# SF32LB55x register map
File version: 1.0
CPU: CM33 r0p1, little endian, MPU, FPU, 3 interrupt priority bits
Registers are 32-bit, read-write, reset 0x0 unless marked. A register's access mark holds for its fields unless they carry their own. Offsets are from the block's base; [hi:lo] are bit positions; {n}, {i} and the like mark numbered series; 'fields as' and 'values as' point back to an identical list.

## EPIC
Base 0x40007000
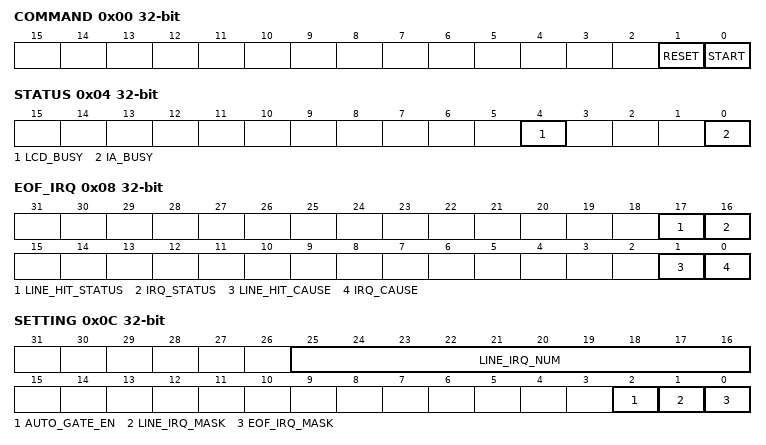
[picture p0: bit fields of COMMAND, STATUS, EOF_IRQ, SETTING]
0x00 COMMAND
  [1] RESET — 1: reset the whole graphics 0: release the reset
  [0] START — write 1 to trigger the lcd interface block
0x04 STATUS
  [4] LCD_BUSY — LCD controll busy flag
  [0] IA_BUSY — Graphics accelerator busy flag
0x08 EOF_IRQ
  [17] LINE_HIT_STATUS — raw status of line hit interrupt
  [16] IRQ_STATUS — raw status of end of frame interrupt
  [1] LINE_HIT_CAUSE — line hit interrupt, can be masked by LINE_IRQ_MASK
  [0] IRQ_CAUSE — end of frame interrupt, can be masked by EOF_IRQ_MASK
0x0C SETTING
  [25:16] LINE_IRQ_NUM — canvas line hit interrupt line number
  [2] AUTO_GATE_EN — auto clock gating enable
  [1] LINE_IRQ_MASK — canvas line hit interrupt mask, 0: mask the interrupt
  [0] EOF_IRQ_MASK — end of frame interrupt mask, 0: mask the interrupt
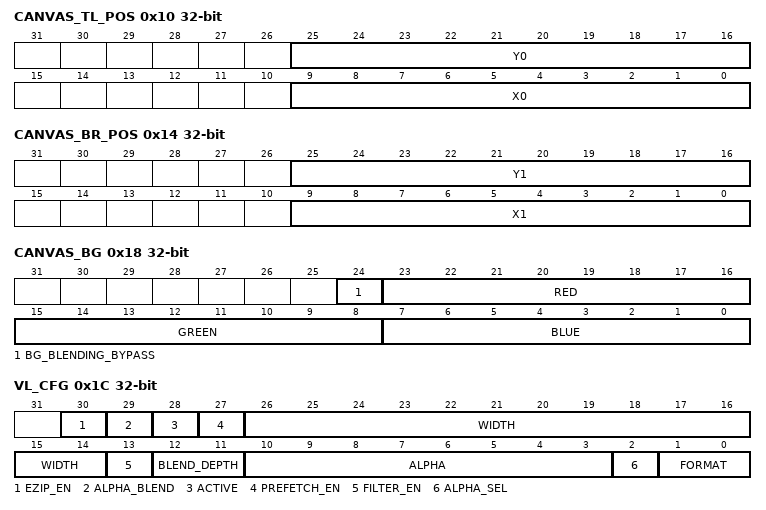
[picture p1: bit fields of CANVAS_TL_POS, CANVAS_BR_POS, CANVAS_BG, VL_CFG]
0x10 CANVAS_TL_POS — Top-Left pixel coordinate
  [25:16] Y0, [9:0] X0
0x14 CANVAS_BR_POS — Bottom-Right pixel coordinate
  [25:16] Y1, [9:0] X1
0x18 CANVAS_BG — Background color
  [24] BG_BLENDING_BYPASS — if this bit is set, the layer is not blending with background. The alpha value will be reserved to output.
  [23:16] RED — Red color
  [15:8] GREEN — green color
  [7:0] BLUE — blue color
0x1C VL_CFG
  [30] EZIP_EN — enable EZIP. EZIP can only be enable for one layer, the order is VL > L0 > L1 > L2
  [29] ALPHA_BLEND — set 1 to enable alpha blending mode. Use layer alpha as blending factor for ARGB8888 and ARGB8565 image. Alpha_out = Layer_alpha * Image_alpha
  [28] ACTIVE — layer active flag
  [27] PREFETCH_EN — preload 64 bytes extra data when reading pixel from memory
  [26:14] WIDTH — source image width(including padding), unit is bytes
  [13] FILTER_EN — layer color filter enable
  [12:11] BLEND_DEPTH — video layer blending depth
  [10:3] ALPHA — layer alpha value
  [2] ALPHA_SEL — alpha selection 1'b0: select alpha according to image format 1'b1: select layer alpha
  [1:0] FORMAT — video layer input format 2'h0: RGB565 2'h1: RGB888 2'h2: ARGB8888 2'h3: ARGB8565
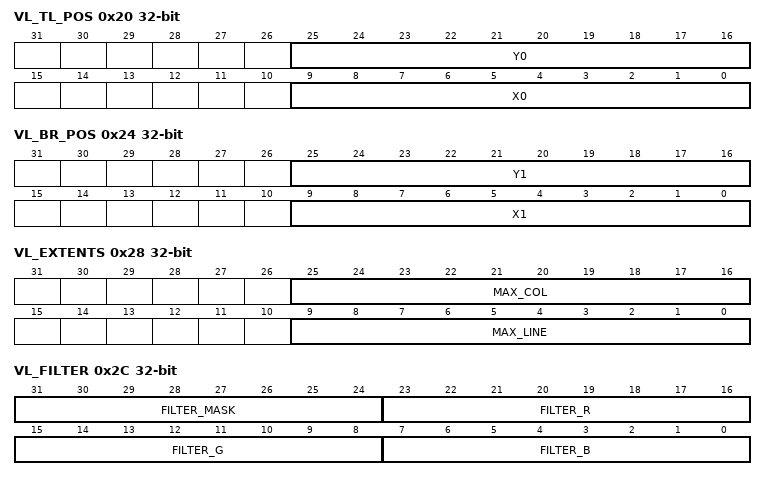
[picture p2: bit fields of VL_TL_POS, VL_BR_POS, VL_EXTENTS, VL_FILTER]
0x20 VL_TL_POS
  [25:16] Y0 — Coordingate Y-value
  [9:0] X0 — Coordinate X-value
0x24 VL_BR_POS
  [25:16] Y1 — Coordingate Y-value
  [9:0] X1 — Coordinate X-value
0x28 VL_EXTENTS
  [25:16] MAX_COL — number of pixels of each line of source image(not including padding)
  [9:0] MAX_LINE — number of pixels of each column of source image(not including padding)
0x2C VL_FILTER
  [31:24] FILTER_MASK — layer color filter mask
  [23:16] FILTER_R — filter r color
  [15:8] FILTER_G — filter g color
  [7:0] FILTER_B — filter b color
0x30 VL_SRC
  [31:0] ADDR — source image RGB data address[31:0]. For RGB565 format, address should be aligned to halfword. For ARGB8888 format, address should be aligned to word.
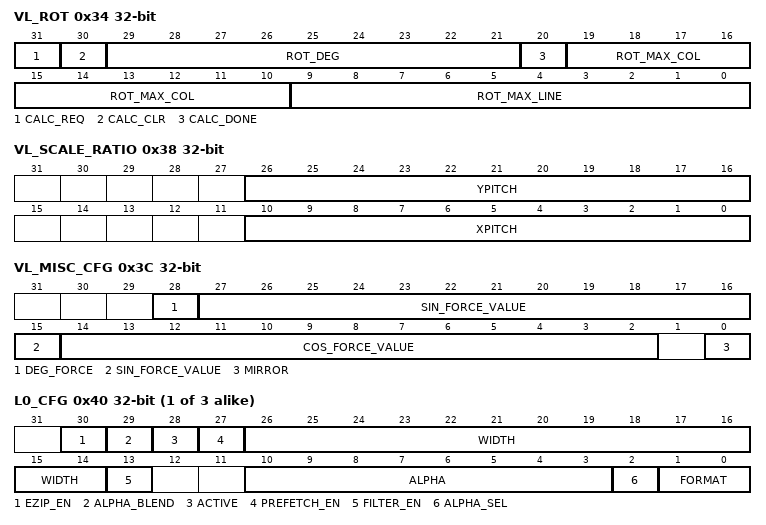
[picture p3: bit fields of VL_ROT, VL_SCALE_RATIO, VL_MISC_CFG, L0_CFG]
0x34 VL_ROT
  [31] CALC_REQ — rot_max_col and rot_max_line calculation request. Write 1 to trigger the calculation.
  [30] CALC_CLR — rot_max_col and rot_max_line calculation clear request. Write 1 to clear the result.
  [29:21] ROT_DEG — rotation degree, rotation is clockwise.
  [20] CALC_DONE — calculation done indicator
  [19:10] ROT_MAX_COL — max column of rotated image
  [9:0] ROT_MAX_LINE — max line of rotated image
0x38 VL_SCALE_RATIO
  [26:16] YPITCH — x-axis rescaling ratio, 3.8 fixed point number, YPITCH lt MAX_LINE/(Y1-Y0)
  [10:0] XPITCH — y-axis rescaling ration, 3.8 fixed point number, XPITCH lt MAX_COL/(X1-X0)
0x3C VL_MISC_CFG
  [28] DEG_FORCE — force epic use external sin and cos value, quadrant is still calculated from ROT_DEG.
  [27:15] SIN_FORCE_VALUE — external absolute value of sin. U13.12 format.
  [14:2] COS_FORCE_VALUE — external absolute value of cos. U13.12 format.
  [0] MIRROR — mirror enable
{0x40+0x14*i} L{i}_CFG (i=0..2)
  [30] EZIP_EN — enable EZIP. EZIP can only be enable for one layer, the order is VL > L0 > L1 > L2
  [29] ALPHA_BLEND — set 1 to enable alpha blending mode. Use layer alpha as blending factor for ARGB8888 and ARGB8565 image. Alpha_out = Layer_alpha * Image_alpha
  [28] ACTIVE — layer active flag
  [27] PREFETCH_EN — preload 64 bytes extra data when reading pixel from memory
  [26:14] WIDTH — source image width(including padding), unit is bytes
  [13] FILTER_EN — layer color filter enable
  [10:3] ALPHA — layer alpha value
  [2] ALPHA_SEL — alpha selection 1'b0: select alpha according to image format 1'b1: select layer alpha
  [1:0] FORMAT — video layer input format 2'h0: RGB565 2'h1: RGB888 2'h2: ARGB8888 2'h3: ARGB8565
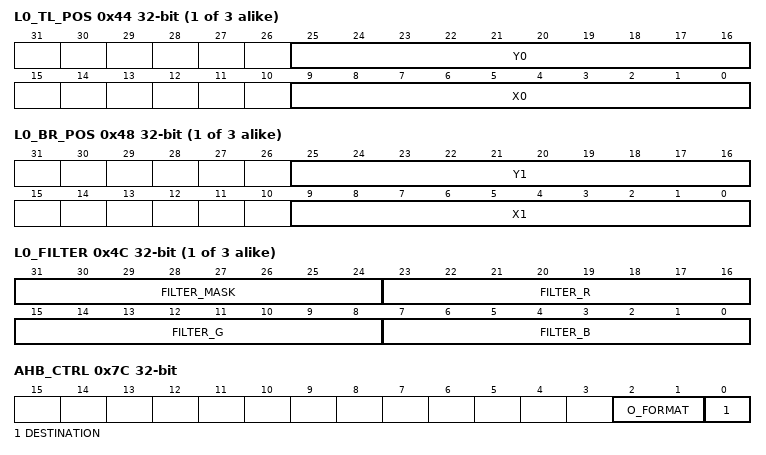
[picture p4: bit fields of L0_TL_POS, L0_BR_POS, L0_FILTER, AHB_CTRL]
{0x44+0x14*i} L{i}_TL_POS (i=0..2)
  [25:16] Y0 — Coordingate Y-value
  [9:0] X0 — Coordinate X-value
{0x48+0x14*i} L{i}_BR_POS (i=0..2)
  [25:16] Y1 — Coordingate Y-value
  [9:0] X1 — Coordinate X-value
{0x4C+0x14*i} L{i}_FILTER (i=0..2)
  fields as VL_FILTER
{0x50+0x14*i} L{i}_SRC (i=0..2)
  fields as VL_SRC
0x7C AHB_CTRL
  [2:1] O_FORMAT — AHB output format: 2'h0: RGB565 2'h1: RGB888 2'h2: ARGB8888 2'h3: ARGB8565
  [0] DESTINATION — The Data can be sent to two destinations: 2'b0: AHB RAM 2'b1: AHB LCD
0x80 AHB_MEM
  [31:0] ADDR — AHB RAM/AHB LCD target address
0x84 AHB_STRIDE
  [15:0] OFFSET
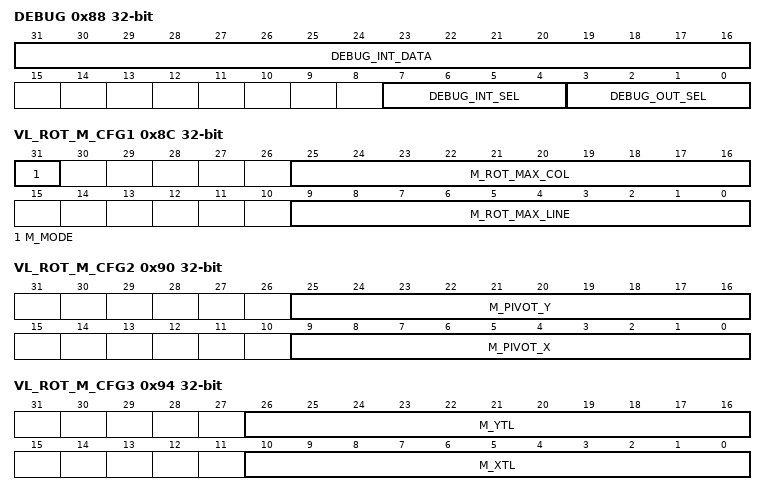
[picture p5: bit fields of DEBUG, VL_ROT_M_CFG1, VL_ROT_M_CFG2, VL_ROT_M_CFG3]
0x88 DEBUG
  [31:16] DEBUG_INT_DATA — 4'h0: RSVD 4'h1: OL0 debug info 4'h2: OL1 debug info 4'h3: OL2 debug info 4'h4: VL debug info1 4'h5: VL debug info2 4'h6: ROI debug out 4'h7: mem intfa debug out 4'h8: mem intfb debug out 4'h9: ahb ctrl debug out 4'ha: ROI XX 4'hb: ROI YY 4'hc: EPIC_EZIP debug out others: RSVD
  [7:4] DEBUG_INT_SEL
  [3:0] DEBUG_OUT_SEL
0x8C VL_ROT_M_CFG1
  [31] M_MODE — 1'b0: auto mode 1'b1: manual mode
  [25:16] M_ROT_MAX_COL — manual mode rotation max column, unsigned value
  [9:0] M_ROT_MAX_LINE — manual mode rotation max line, unsigned value
0x90 VL_ROT_M_CFG2
  [25:16] M_PIVOT_Y — manual mode pivot y, unsigned value
  [9:0] M_PIVOT_X — manual mode pivot x, unsigned value
0x94 VL_ROT_M_CFG3
  [26:16] M_YTL — manual mode top left y cordinate, signed value
  [10:0] M_XTL — manual mode top left x cordinate, signed value
